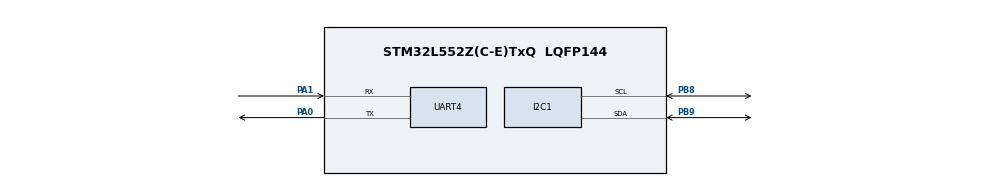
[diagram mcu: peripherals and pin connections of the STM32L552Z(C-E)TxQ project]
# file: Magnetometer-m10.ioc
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I2C1.Timing=0x00100D14
Mcu.Family=STM32L5
Mcu.Name=STM32L552Z(C-E)TxQ
Mcu.Package=LQFP144
NVIC.PriorityGroup=NVIC_PRIORITYGROUP_3
PA0.Mode=Asynchronous
PA0.Signal=UART4_TX
PA1.Mode=Asynchronous
PA1.Signal=UART4_RX
PB8.Mode=I2C
PB8.Signal=I2C1_SCL
PB9.Mode=I2C
PB9.Signal=I2C1_SDA
ProjectManager.HeapSize=0x200
ProjectManager.StackSize=0x400
ProjectManager.TargetToolchain=STM32CubeIDE
RCC.HSE_VALUE=16000000
RCC.HSI48_VALUE=48000000
RCC.HSI_VALUE=16000000
RCC.LSE_VALUE=32768
RCC.MSI_VALUE=4000000
RCC.VCOOutputFreq_Value=32000000
VP_PWR_VS_DBSignals.Mode=DisableDeadBatterySignals
VP_PWR_VS_SECSignals.Mode=Security/Privilege
board=custom

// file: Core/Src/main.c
/* USER CODE BEGIN Header */
/**
  ******************************************************************************
  * @file           : main.c
  * @brief          : Main program body
  ******************************************************************************
  * @attention
  *
  * Copyright (c) 2026 STMicroelectronics.
  * All rights reserved.
  *
  * This software is licensed under terms that can be found in the LICENSE file
  * in the root directory of this software component.
  * If no LICENSE file comes with this software, it is provided AS-IS.
  *
  ******************************************************************************
  */
/* USER CODE END Header */
#include "main.h"

/* USER CODE BEGIN Includes */
#include "ist8310_i2c.hpp"
/* USER CODE END Includes */

I2C_HandleTypeDef hi2c1;

UART_HandleTypeDef huart4;

/* USER CODE BEGIN PV */
volatile float mag_x = 0;
volatile float mag_y = 0;
volatile float mag_z = 0;
volatile float mag_heading = 0;
volatile bool mag_ok = false;
/* USER CODE END PV */

void SystemClock_Config(void);
static void MX_GPIO_Init(void);
static void MX_I2C1_Init(void);
static void MX_UART4_Init(void);

int main(void)
{

  /* MCU Configuration--------------------------------------------------------*/

  /* Reset of all peripherals, Initializes the Flash interface and the Systick. */
  HAL_Init();

  /* Configure the system clock */
  SystemClock_Config();

  /* Initialize all configured peripherals */
  MX_GPIO_Init();
  MX_I2C1_Init();
  MX_UART4_Init();
  /* USER CODE BEGIN 2 */
  ist8310_i2cmag(&hi2c1);
  mag_ok = mag.init()
  /* USER CODE END 2 */

  /* Infinite loop */
  while (1)
  {
    mag.read();
    mag_x = mag.get_x_data();
    mag_y = mag.get_y_data();
    mag_z = mag.get_z_data();
    mag_heading = mag.get_heading();

    HAL_Delay(10);
  }
}

void SystemClock_Config(void)
{
  RCC_OscInitTypeDef RCC_OscInitStruct = {0};
  RCC_ClkInitTypeDef RCC_ClkInitStruct = {0};

  /** Configure the main internal regulator output voltage
  */
  if (HAL_PWREx_ControlVoltageScaling(PWR_REGULATOR_VOLTAGE_SCALE2) != HAL_OK)
  {
    Error_Handler();
  }

  /** Initializes the RCC Oscillators according to the specified parameters
  * in the RCC_OscInitTypeDef structure.
  */
  RCC_OscInitStruct.OscillatorType = RCC_OSCILLATORTYPE_MSI;
  RCC_OscInitStruct.MSIState = RCC_MSI_ON;
  RCC_OscInitStruct.MSICalibrationValue = RCC_MSICALIBRATION_DEFAULT;
  RCC_OscInitStruct.MSIClockRange = RCC_MSIRANGE_6;
  RCC_OscInitStruct.PLL.PLLState = RCC_PLL_NONE;
  if (HAL_RCC_OscConfig(&RCC_OscInitStruct) != HAL_OK)
  {
    Error_Handler();
  }

  /** Initializes the CPU, AHB and APB buses clocks
  */
  RCC_ClkInitStruct.ClockType = RCC_CLOCKTYPE_HCLK|RCC_CLOCKTYPE_SYSCLK
                              |RCC_CLOCKTYPE_PCLK1|RCC_CLOCKTYPE_PCLK2;
  RCC_ClkInitStruct.SYSCLKSource = RCC_SYSCLKSOURCE_MSI;
  RCC_ClkInitStruct.AHBCLKDivider = RCC_SYSCLK_DIV1;
  RCC_ClkInitStruct.APB1CLKDivider = RCC_HCLK_DIV1;
  RCC_ClkInitStruct.APB2CLKDivider = RCC_HCLK_DIV1;

  if (HAL_RCC_ClockConfig(&RCC_ClkInitStruct, FLASH_LATENCY_0) != HAL_OK)
  {
    Error_Handler();
  }
}

static void MX_I2C1_Init(void)
{

  hi2c1.Instance = I2C1;
  hi2c1.Init.Timing = 0x00100D14;
  hi2c1.Init.OwnAddress1 = 0;
  hi2c1.Init.AddressingMode = I2C_ADDRESSINGMODE_7BIT;
  hi2c1.Init.DualAddressMode = I2C_DUALADDRESS_DISABLE;
  hi2c1.Init.OwnAddress2 = 0;
  hi2c1.Init.OwnAddress2Masks = I2C_OA2_NOMASK;
  hi2c1.Init.GeneralCallMode = I2C_GENERALCALL_DISABLE;
  hi2c1.Init.NoStretchMode = I2C_NOSTRETCH_DISABLE;
  if (HAL_I2C_Init(&hi2c1) != HAL_OK)
  {
    Error_Handler();
  }

  /** Configure Analogue filter
  */
  if (HAL_I2CEx_ConfigAnalogFilter(&hi2c1, I2C_ANALOGFILTER_ENABLE) != HAL_OK)
  {
    Error_Handler();
  }

  /** Configure Digital filter
  */
  if (HAL_I2CEx_ConfigDigitalFilter(&hi2c1, 0) != HAL_OK)
  {
    Error_Handler();
  }

}

static void MX_UART4_Init(void)
{

  huart4.Instance = UART4;
  huart4.Init.BaudRate = 115200;
  huart4.Init.WordLength = UART_WORDLENGTH_8B;
  huart4.Init.StopBits = UART_STOPBITS_1;
  huart4.Init.Parity = UART_PARITY_NONE;
  huart4.Init.Mode = UART_MODE_TX_RX;
  huart4.Init.HwFlowCtl = UART_HWCONTROL_NONE;
  huart4.Init.OverSampling = UART_OVERSAMPLING_16;
  huart4.Init.OneBitSampling = UART_ONE_BIT_SAMPLE_DISABLE;
  huart4.Init.ClockPrescaler = UART_PRESCALER_DIV1;
  huart4.AdvancedInit.AdvFeatureInit = UART_ADVFEATURE_NO_INIT;
  if (HAL_UART_Init(&huart4) != HAL_OK)
  {
    Error_Handler();
  }
  if (HAL_UARTEx_SetTxFifoThreshold(&huart4, UART_TXFIFO_THRESHOLD_1_8) != HAL_OK)
  {
    Error_Handler();
  }
  if (HAL_UARTEx_SetRxFifoThreshold(&huart4, UART_RXFIFO_THRESHOLD_1_8) != HAL_OK)
  {
    Error_Handler();
  }
  if (HAL_UARTEx_DisableFifoMode(&huart4) != HAL_OK)
  {
    Error_Handler();
  }

}

static void MX_GPIO_Init(void)
{

  /* GPIO Ports Clock Enable */
  __HAL_RCC_GPIOA_CLK_ENABLE();
  __HAL_RCC_GPIOB_CLK_ENABLE();

}

void Error_Handler(void)
{
  __disable_irq();
  while (1)
  {
  }
}
